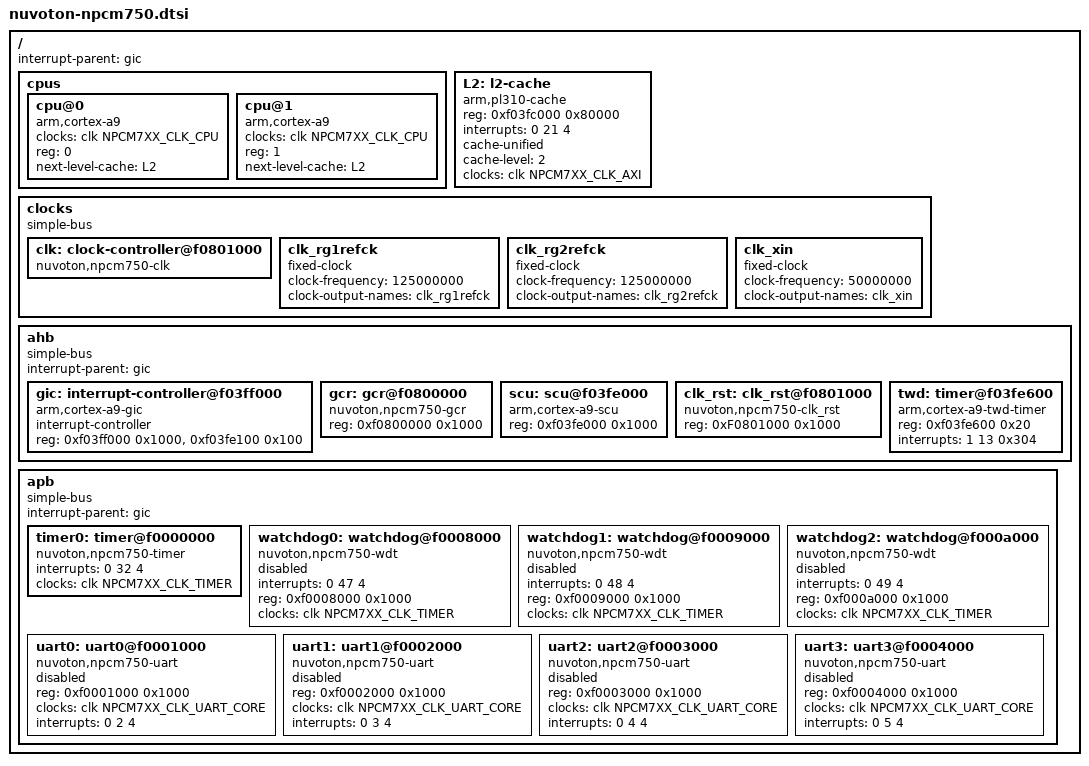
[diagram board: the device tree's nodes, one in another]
/*
 * DTSi file for the NPCM750 SoC
 *
 * Copyright 2012 Tomer Maimon <tomer.maimon@nuvoton.com>
 *
 * The code contained herein is licensed under the GNU General Public
 * License. You may obtain a copy of the GNU General Public License
 * Version 2 or later at the following locations:
 *
 * http://www.opensource.org/licenses/gpl-license.html
 * http://www.gnu.org/copyleft/gpl.html
 */

#include "skeleton.dtsi"
#include <dt-bindings/interrupt-controller/arm-gic.h>
#include <dt-bindings/clock/nuvoton,npcm7xx-clks.h>

/ {
	interrupt-parent = <&gic>;

	cpus {
		#address-cells = <1>;
		#size-cells = <0>;

		cpu@0 {
			device_type = "cpu";
			compatible = "arm,cortex-a9";
			clocks = <&clk NPCM7XX_CLK_CPU>;
			clock-names = "clk_cpu";
			reg = <0>;
			next-level-cache = <&L2>;
		};

		cpu@1 {
			device_type = "cpu";
			compatible = "arm,cortex-a9";
			clocks = <&clk NPCM7XX_CLK_CPU>;
			clock-names = "clk_cpu";
			reg = <1>;
			next-level-cache = <&L2>;
		};

	};

	L2: l2-cache {
		compatible = "arm,pl310-cache";
		reg = <0xf03fc000 0x80000>;
		interrupts = <0 21 4>;
		cache-unified;
		cache-level = <2>;
		clocks = <&clk NPCM7XX_CLK_AXI>;
		clock-names = "clk_axi";
	    };

	    clocks {
		compatible = "simple-bus";
		#address-cells = <1>;
		#size-cells = <1>;
		ranges;

		clk: clock-controller@f0801000 {
			compatible = "nuvoton,npcm750-clk";
			#clock-cells = <1>;
		};

		/* external clock signal rg1refck, supplied by the phy */
		clk_rg1refck: clk_rg1refck {
			compatible = "fixed-clock";
			#clock-cells = <0>;
			clock-frequency = <125000000>;
			clock-output-names = "clk_rg1refck";
		};

		/* external clock signal rg2refck, supplied by the phy */
		clk_rg2refck: clk_rg2refck {
			compatible = "fixed-clock";
			#clock-cells = <0>;
			clock-frequency = <125000000>;
			clock-output-names = "clk_rg2refck";
		};

		clk_xin: clk_xin {
			compatible = "fixed-clock";
			#clock-cells = <0>;
			clock-frequency = <50000000>;
			clock-output-names = "clk_xin";
		};
	};

	ahb {
		#address-cells = <1>;
		#size-cells = <1>;
		compatible = "simple-bus";
		interrupt-parent = <&gic>;
		ranges = <0x80000000 0x80000000 0x20000000 /* AHB18 */
			0xa0000000 0xa0000000 0x28000000 /* AHB3  */
			0xe0000000 0xe0000000 0x10000000 /* AHB14 */
			0xf0000000 0xf0000000 0x00800000 /* AHB1  */
			0xf0800000 0xf0800000 0x00800000 /* AHB8  */
			0xf8000000 0xf8000000 0x04000000  /* AHB18 - cont */
			0xfffd0000 0xfffd0000 0x00040000>;   /* RAM2 */

		gic: interrupt-controller@f03ff000 {
			compatible = "arm,cortex-a9-gic";
			interrupt-controller;
			#interrupt-cells = <3>;
			reg = <0xf03ff000 0x1000>,
			    <0xf03fe100 0x100>;
		};

		gcr: gcr@f0800000 {
			#address-cells = <1>;
			#size-cells = <1>;
			compatible = "nuvoton,npcm750-gcr", "syscon",
				"simple-mfd";
			reg = <0xf0800000 0x1000>;
		};

		scu: scu@f03fe000 {
			#address-cells = <1>;
			#size-cells = <1>;
			compatible = "arm,cortex-a9-scu";
			reg = <0xf03fe000 0x1000>;
		};

		clk_rst: clk_rst@f0801000 {
			#address-cells = <1>;
			#size-cells = <1>;
			compatible = "nuvoton,npcm750-clk_rst", "syscon",
				"simple-mfd";
			reg = <0xF0801000 0x1000>;
		};

		twd: timer@f03fe600 {
			compatible = "arm,cortex-a9-twd-timer";
			reg = <0xf03fe600 0x20>;
			interrupts = <1 13 0x304>;
		};
	};

	apb {
		#address-cells = <1>;
		#size-cells = <1>;
		compatible = "simple-bus";
		interrupt-parent = <&gic>;
		ranges = <0xf0000000 0xf0000000 0x00080000
			0xf0080000 0xf0080000 0x00080000
			0xf0100000 0xf0100000 0x00080000
			0xf0180000 0xf0180000 0x00080000
			0xf0200000 0xf0200000 0x00600000>;

		timer0: timer@f0000000 {
			compatible = "nuvoton,npcm750-timer";
			interrupts = <0 32 4>;
			clocks = <&clk NPCM7XX_CLK_TIMER>;
			clock-names = "clk_timer";
		};

		watchdog0: watchdog@f0008000 {
			compatible = "nuvoton,npcm750-wdt";
			interrupts = <0 47 4>;
			reg = <0xf0008000 0x1000>;
			status = "disabled";
			clocks = <&clk NPCM7XX_CLK_TIMER>;
			clock-names = "clk_timer";
		};

		watchdog1: watchdog@f0009000 {
			compatible = "nuvoton,npcm750-wdt";
			interrupts = <0 48 4>;
			reg = <0xf0009000 0x1000>;
			status = "disabled";
			clocks = <&clk NPCM7XX_CLK_TIMER>;
			clock-names = "clk_timer";
		};

		watchdog2: watchdog@f000a000 {
			compatible = "nuvoton,npcm750-wdt";
			interrupts = <0 49 4>;
			reg = <0xf000a000 0x1000>;
			status = "disabled";
			clocks = <&clk NPCM7XX_CLK_TIMER>;
			clock-names = "clk_timer";
		};

		uart0: uart0@f0001000 {
			compatible = "nuvoton,npcm750-uart";
			reg = <0xf0001000 0x1000>;
			clocks = <&clk NPCM7XX_CLK_UART_CORE>;
			clock-names = "clk_uart";
			interrupts = <0 2 4>;
			status = "disabled";
		};

		uart1: uart1@f0002000 {
			compatible = "nuvoton,npcm750-uart";
			reg = <0xf0002000 0x1000>;
			clocks = <&clk NPCM7XX_CLK_UART_CORE>;
			clock-names = "clk_uart";
			interrupts = <0 3 4>;
			status = "disabled";
		};

		uart2: uart2@f0003000 {
			compatible = "nuvoton,npcm750-uart";
			reg = <0xf0003000 0x1000>;
			clocks = <&clk NPCM7XX_CLK_UART_CORE>;
			clock-names = "clk_uart";
			interrupts = <0 4 4>;
			status = "disabled";
		};

		uart3: uart3@f0004000 {
			compatible = "nuvoton,npcm750-uart";
			reg = <0xf0004000 0x1000>;
			clocks = <&clk NPCM7XX_CLK_UART_CORE>;
			clock-names = "clk_uart";
			interrupts = <0 5 4>;
			status = "disabled";
		};
	};
};
